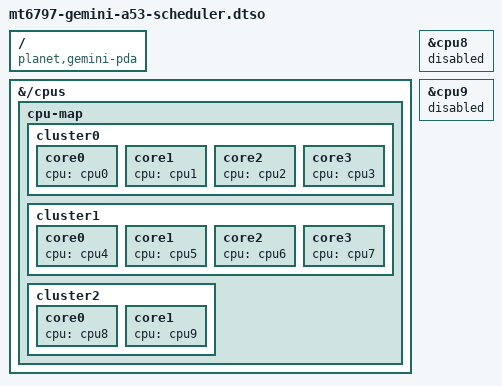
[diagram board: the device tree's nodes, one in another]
// SPDX-License-Identifier: (GPL-2.0-only OR MIT)
/*
 * Planet Computers Gemini PDA A53 scheduler-topology candidate.
 *
 * Apply this overlay only after the A53 DVFS preflight has passed, together
 * with mt6797-gemini-a53-dvfs-activation.dtbo in a volatile FIT. The topology
 * follows the MPIDR affinities and cpu-map in the pinned MT6797 vendor DT. Its
 * arm64 scheduler does contain exact Cortex-A53 and Cortex-A72 efficiency
 * constants, but capacity-dmips-mhz is deliberately absent. CPU8/9 remain
 * possible while their CPU_ON and cpufreq policy are gated, so the generic
 * capacity notifier cannot finish max-frequency normalization. Publishing
 * the constants in that state would therefore be misleading. No dynamic
 * power coefficient or energy model is asserted here.
 */

/dts-v1/;
/plugin/;

/ {
	compatible = "planet,gemini-pda", "mediatek,mt6797";
};

&{/cpus} {
	cpu-map {
		cluster0 {
			core0 {
				cpu = <&cpu0>;
			};

			core1 {
				cpu = <&cpu1>;
			};

			core2 {
				cpu = <&cpu2>;
			};

			core3 {
				cpu = <&cpu3>;
			};
		};

		cluster1 {
			core0 {
				cpu = <&cpu4>;
			};

			core1 {
				cpu = <&cpu5>;
			};

			core2 {
				cpu = <&cpu6>;
			};

			core3 {
				cpu = <&cpu7>;
			};
		};

		cluster2 {
			core0 {
				cpu = <&cpu8>;
			};

			core1 {
				cpu = <&cpu9>;
			};
		};
	};
};

&cpu8 {
	status = "disabled";
};

&cpu9 {
	status = "disabled";
};
